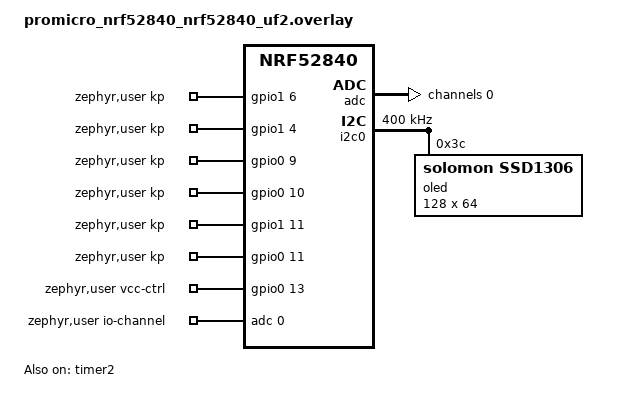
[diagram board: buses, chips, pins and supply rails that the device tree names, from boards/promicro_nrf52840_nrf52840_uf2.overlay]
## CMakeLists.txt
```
cmake_minimum_required(VERSION 3.20.0)
find_package(Zephyr REQUIRED HINTS $ENV{ZEPHYR_BASE})
project(zb_remote)
target_sources(app PRIVATE src/main.c src/buttons.c src/keypad.c src/battery.c src/led.c src/oled.c src/display_cluster.c src/font_terminus12.c src/icons.c)
target_include_directories(app PRIVATE src)
# record ZBOSS asserts (see __wrap_zb_assert in main.c)
zephyr_link_libraries(-Wl,--wrap=zb_assert)
```

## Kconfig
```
menu "zb-remote"
config APP_WAIT_HOST
	bool "Wait up to 20 s for USB host to open the console before starting"
config APP_RAM_PWRDN
	bool "Power down unused RAM"
endmenu
source "Kconfig.zephyr"
```

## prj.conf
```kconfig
CONFIG_GPIO=y
CONFIG_ADC=y
CONFIG_HEAP_MEM_POOL_SIZE=2048
CONFIG_MAIN_THREAD_PRIORITY=7

CONFIG_ZIGBEE_ADD_ON=y
CONFIG_ZIGBEE_APP_UTILS=y
CONFIG_ZIGBEE_ROLE_END_DEVICE=y
CONFIG_RAM_POWER_DOWN_LIBRARY=y

# Battery build (default): no USB, no console, no logs, start immediately.
# Development build with USB CDC logs: west build ... -- -DEXTRA_CONF_FILE=debug.conf
CONFIG_LOG=n
CONFIG_PRINTK=n
CONFIG_BOOT_BANNER=n
CONFIG_NCS_BOOT_BANNER=n
CONFIG_CONSOLE=n
CONFIG_UART_CONSOLE=n
CONFIG_SERIAL=n
CONFIG_USB_DEVICE_STACK=n
CONFIG_USB_DEVICE_STACK_NEXT=n
CONFIG_USB_CDC_ACM=n
CONFIG_APP_WAIT_HOST=n

# own k_sys_fatal_error_handler in main.c (records crash, reboots)
CONFIG_RESET_ON_FATAL_ERROR=n

# Pro Micro clones often have no 32.768 kHz crystal -> use internal RC (calibrated)
CONFIG_CLOCK_CONTROL_NRF_K32SRC_RC=y

# Scan all channels when joining (Z2M network is on channel 11)
CONFIG_ZIGBEE_CHANNEL_SELECTION_MODE_MULTI=y

# Z-Stack 3.x coordinator: classic Zigbee 3.0 (R22) association + transport key
CONFIG_ZIGBEE_PRO_CORE_BEHAVIOR_R22=y

# OLED
CONFIG_I2C=y
CONFIG_DISPLAY=y
CONFIG_HWINFO=y
```

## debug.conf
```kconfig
# Development overlay: logs over USB CDC ACM (/dev/cu.usbmodem*, 115200).
# west build -d build-debug -b promicro_nrf52840/nrf52840/uf2 . -- -DEXTRA_CONF_FILE=debug.conf
CONFIG_LOG=y
# deferred: logging never blocks the app when the USB host is not reading
CONFIG_LOG_MODE_DEFERRED=y
CONFIG_LOG_BUFFER_SIZE=4096
CONFIG_PRINTK=y
CONFIG_BOOT_BANNER=y
CONFIG_NCS_BOOT_BANNER=y
CONFIG_NCS_APPLICATION_BOOT_BANNER_STRING="zb-remote"
CONFIG_CONSOLE=y
CONFIG_UART_CONSOLE=y
CONFIG_SERIAL=y
CONFIG_UART_LINE_CTRL=y
# Legacy USB stack: the new device_next CDC does not enumerate on this Pro Micro clone
CONFIG_USB_DEVICE_STACK_NEXT=n
CONFIG_CDC_ACM_SERIAL_INITIALIZE_AT_BOOT=n
CONFIG_USB_DEVICE_STACK=y
CONFIG_USB_DEVICE_INITIALIZE_AT_BOOT=y
CONFIG_USB_CDC_ACM=y
CONFIG_USB_DEVICE_PRODUCT="zb-remote"
CONFIG_USB_DEVICE_PID=0x0004
# wait up to 20 s for the host to open the port so boot logs are not lost
CONFIG_APP_WAIT_HOST=y
```

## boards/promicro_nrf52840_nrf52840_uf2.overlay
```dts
/* Pro Micro nRF52840 (nice!nano clone), Adafruit UF2 bootloader + S140 v6 region kept.
 * Flash: 0x26000 app .. 0xD0000 | settings 8K | zboss_nvram 32K | zboss product cfg 4K | free | UF2 @0xF4000
 */
/delete-node/ &storage_partition;

&code_partition {
	reg = <0x00026000 0x000aa000>;
};

&flash0 {
	partitions {
		storage_partition: partition@d0000 {
			label = "storage";
			reg = <0x000d0000 0x00002000>;
		};
		zboss_nvram: partition@d2000 {
			label = "zboss-nvram";
			reg = <0x000d2000 0x00008000>;
		};
		zboss_product_config: partition@da000 {
			label = "zboss-product-config";
			reg = <0x000da000 0x00001000>;
		};
	};
};

/ {
	chosen {
		ncs,zigbee-timer = &timer2;
	};

	zephyr,user {
		/* Keypad: the 8 pads of the removed remote IC, pad 1..8 -> these pins (left header).
		 * Every pair of lines is scanned, buttons = pairs (see src/keymap.h). */
		kp-gpios = <&gpio1 6  GPIO_PULL_UP>,  /* 106 (left, bottom)   -> line 1 = IC GND */
			   <&gpio1 4  GPIO_PULL_UP>,  /* 104 (left, 2nd)      -> line 2 */
			   <&gpio0 9  GPIO_PULL_UP>,  /* 009 (right, bottom)  -> line 3 (NFC pin, board sets nfct-pins-as-gpios) */
			   <&gpio0 10 GPIO_PULL_UP>,  /* 010 (right, 2nd)     -> line 4 (NFC pin) */
			   <&gpio1 11 GPIO_PULL_UP>,  /* 111 (right, 3rd)     -> line 5 */
			   <&gpio0 11 GPIO_PULL_UP>;  /* 011 (left, 3rd)      -> line 6 */
		/* External VCC switch (powers the OLED) */
		vcc-ctrl-gpios = <&gpio0 13 GPIO_ACTIVE_HIGH>;
		io-channels = <&adc 0>;
	};
};

&timer2 {
	status = "okay";
};

/* UART0 (P0.09/P0.10) not used */
&uart0 {
	status = "disabled";
};

/* OLED on I2C0: SDA P0.17 (D2), SCL P0.20 (D3) */
&pinctrl {
	i2c0_default: i2c0_default {
		group1 {
			psels = <NRF_PSEL(TWIM_SDA, 0, 17)>,
				<NRF_PSEL(TWIM_SCL, 0, 20)>;
		};
	};
	i2c0_sleep: i2c0_sleep {
		group1 {
			psels = <NRF_PSEL(TWIM_SDA, 0, 17)>,
				<NRF_PSEL(TWIM_SCL, 0, 20)>;
			low-power-enable;
		};
	};
};

/* Battery: VDDH/5 */
&adc {
	#address-cells = <1>;
	#size-cells = <0>;
	status = "okay";
	channel@0 {
		reg = <0>;
		zephyr,gain = "ADC_GAIN_1_6";
		zephyr,reference = "ADC_REF_INTERNAL";
		zephyr,acquisition-time = <ADC_ACQ_TIME(ADC_ACQ_TIME_MICROSECONDS, 40)>;
		zephyr,input-positive = <NRF_SAADC_VDDHDIV5>;
		zephyr,resolution = <12>;
	};
};

/* Buttons use PORT/SENSE instead of GPIOTE IN channels (only 8 exist, we need 14) */
&gpio0 {
	sense-edge-mask = <0xffffffff>;
};
&gpio1 {
	sense-edge-mask = <0x0000ffff>;
};

/ {
	chosen {
		zephyr,display = &oled;
	};
};

&i2c0 {
	status = "okay";
	clock-frequency = <I2C_BITRATE_FAST>;
	oled: ssd1306@3c {
		compatible = "solomon,ssd1306";
		reg = <0x3c>;
		width = <128>;
		height = <64>;
		segment-offset = <0>;
		page-offset = <0>;
		display-offset = <0>;
		multiplex-ratio = <63>;
		segment-remap;
		com-invdir;
		prechargep = <0xf1>;
		zephyr,deferred-init;
	};
};
```

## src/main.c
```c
/* zb-remote: 14-button sleepy Zigbee remote (nRF52840 Pro Micro) for Zigbee2MQTT.
 *
 * Endpoint 1, HA profile, device "Remote Control":
 *   Basic, Identify, Power Config (battery), Multistate Input (button actions).
 * Button action -> Report Attributes genMultistateInput.presentValue = btn*10 + action
 *   action: 1 single, 2 double, 3 hold.
 */
#include <zephyr/kernel.h>
#include <zephyr/logging/log.h>
#include <stdio.h>

#include <zboss_api.h>
#include <zboss_api_addons.h>
#include <zigbee/zigbee_error_handler.h>
#include <zigbee/zigbee_app_utils.h>
#include <zb_nrf_platform.h>
#include <ram_pwrdn.h>

#include "buttons.h"
#include "keypad.h"
#include "keymap.h"
#include <zephyr/sys/reboot.h>
#include "battery.h"
#include "led.h"
#include "oled.h"
#include "display_cluster.h"
#include <zephyr/drivers/uart.h>
#include <zephyr/drivers/hwinfo.h>
#include <zephyr/fatal.h>
#include <zephyr/storage/flash_map.h>
#include <hal/nrf_power.h>
#include <zephyr/sys/reboot.h>

LOG_MODULE_REGISTER(app, LOG_LEVEL_INF);

/* last fatal error survives the software reset (noinit RAM) and is logged on the next boot */
static __noinit struct {
	uint32_t magic, reason, pc, lr, thread;
} crash;
#define CRASH_MAGIC 0xC0FFEE11

void k_sys_fatal_error_handler(unsigned int reason, const struct arch_esf *esf)
{
	crash.magic = CRASH_MAGIC;
	crash.reason = reason;
	crash.pc = esf ? esf->basic.pc : 0;
	crash.lr = esf ? esf->basic.lr : 0;
	crash.thread = (uint32_t)k_current_get();
	sys_reboot(SYS_REBOOT_COLD);
}

/* ZBOSS internal assert (linked with --wrap=zb_assert) -> remembered across the reset */
extern void __real_zb_assert(zb_uint16_t file_id, zb_int_t line);
void __wrap_zb_assert(zb_uint16_t file_id, zb_int_t line)
{
	crash.magic = CRASH_MAGIC;
	crash.reason = 0xA55E;
	crash.pc = file_id;
	crash.lr = (uint32_t)line;
	crash.thread = 0;
	if (!k_is_in_isr()) {
		LOG_ERR("ZBOSS assert file_id %u line %d, rebooting in 1 s", file_id, line);
		k_msleep(1000); /* let the USB console flush the log */
	}
	__real_zb_assert(file_id, line);
}


/* file_id 122 = zb_nvram.c: corrupted NVRAM makes ZBOSS assert on every boot.
 * Wipe the partition once so the stack starts clean (network has to be re-joined). */
#define ZB_FILE_ID_NVRAM 122
static int erase_partition(uint8_t id, const char *name)
{
	const struct flash_area *fa;
	int err = flash_area_open(id, &fa);
	if (!err) {
		err = flash_area_erase(fa, 0, fa->fa_size);
		flash_area_close(fa);
	}
	LOG_WRN("%s erased: %d", name, err);
	return err;
}

/* NVRAM datasets are encrypted with a PSA master key kept in trusted storage (settings/NVS
 * in the "storage" partition); if either is corrupted the stack asserts while saving keys.
 * Wipe both together: the device leaves the network and has to be re-joined. */
static void nvram_self_heal(void)
{
	erase_partition(FIXED_PARTITION_ID(zboss_nvram), "zboss nvram");
	erase_partition(FIXED_PARTITION_ID(storage_partition), "settings storage (PSA ITS)");
	/* settings/NVS may already be mounted on the old content -> restart clean */
	crash.magic = 0;
	k_msleep(500);
	sys_reboot(SYS_REBOOT_COLD);
}


#define EP                 1
#define DEVICE_ID          0x0006 /* HA Remote Control */
#define LONG_POLL_MS       5000
#define FAST_POLL_MS       100   /* while the screen is on after a press */
#define FAST_POLL_FOR      K_SECONDS(10)
#define BATTERY_PERIOD     K_HOURS(1)


/* ---------- attributes ---------- */
static struct {
	zb_uint8_t zcl_version;
	zb_uint8_t app_version;
	zb_uint8_t stack_version;
	zb_uint8_t hw_version;
	zb_char_t mf_name[16];
	zb_char_t model_id[16];
	zb_char_t date_code[10];
	zb_uint8_t power_source;
	zb_char_t location_id[2];
	zb_uint8_t ph_env;
	zb_char_t sw_build_id[12];
} basic;

static zb_uint16_t identify_time;

static struct {
	zb_uint8_t voltage;       /* 100 mV units */
	zb_uint8_t size;
	zb_uint8_t quantity;
	zb_uint8_t rated_voltage;
	zb_uint8_t alarm_mask;
	zb_uint8_t voltage_min_th;
	zb_uint8_t remaining;     /* 0.5 % units */
	zb_uint8_t th1, th2, th3, min_th, pth1, pth2, pth3;
	zb_uint32_t alarm_state;
} batt;

static struct {
	zb_char_t description[2];
	zb_uint16_t num_states;
	zb_bool_t out_of_service;
	zb_uint16_t present_value;
	zb_uint8_t reliability;
	zb_uint8_t status_flags;
	zb_uint32_t app_type;
} msi;

ZB_ZCL_DECLARE_BASIC_ATTRIB_LIST_EXT(basic_attr_list, &basic.zcl_version, &basic.app_version,
	&basic.stack_version, &basic.hw_version, basic.mf_name, basic.model_id, basic.date_code,
	&basic.power_source, basic.location_id, &basic.ph_env, basic.sw_build_id);

ZB_ZCL_DECLARE_IDENTIFY_ATTRIB_LIST(identify_attr_list, &identify_time);

ZB_ZCL_START_DECLARE_ATTRIB_LIST_CLUSTER_REVISION(power_attr_list, ZB_ZCL_POWER_CONFIG)
ZB_ZCL_POWER_CONFIG_BATTERY_ATTRIB_LIST_EXT(, &batt.voltage, &batt.size,
	&batt.quantity, &batt.rated_voltage, &batt.alarm_mask, &batt.voltage_min_th, &batt.remaining,
	&batt.th1, &batt.th2, &batt.th3, &batt.min_th, &batt.pth1, &batt.pth2, &batt.pth3,
	&batt.alarm_state)
ZB_ZCL_FINISH_DECLARE_ATTRIB_LIST;

ZB_ZCL_DECLARE_MULTI_INPUT_ATTRIB_LIST(msi_attr_list, msi.description, &msi.num_states,
	&msi.out_of_service, &msi.present_value, &msi.reliability, &msi.status_flags, &msi.app_type);

static zb_zcl_cluster_desc_t clusters[] = {
	ZB_ZCL_CLUSTER_DESC(ZB_ZCL_CLUSTER_ID_BASIC, ZB_ZCL_ARRAY_SIZE(basic_attr_list, zb_zcl_attr_t),
			    basic_attr_list, ZB_ZCL_CLUSTER_SERVER_ROLE, ZB_ZCL_MANUF_CODE_INVALID),
	ZB_ZCL_CLUSTER_DESC(ZB_ZCL_CLUSTER_ID_IDENTIFY,
			    ZB_ZCL_ARRAY_SIZE(identify_attr_list, zb_zcl_attr_t), identify_attr_list,
			    ZB_ZCL_CLUSTER_SERVER_ROLE, ZB_ZCL_MANUF_CODE_INVALID),
	ZB_ZCL_CLUSTER_DESC(ZB_ZCL_CLUSTER_ID_POWER_CONFIG,
			    ZB_ZCL_ARRAY_SIZE(power_attr_list, zb_zcl_attr_t), power_attr_list,
			    ZB_ZCL_CLUSTER_SERVER_ROLE, ZB_ZCL_MANUF_CODE_INVALID),
	ZB_ZCL_CLUSTER_DESC(ZB_ZCL_CLUSTER_ID_MULTI_INPUT,
			    ZB_ZCL_ARRAY_SIZE(msi_attr_list, zb_zcl_attr_t), msi_attr_list,
			    ZB_ZCL_CLUSTER_SERVER_ROLE, ZB_ZCL_MANUF_CODE_INVALID),
	ZB_ZCL_CLUSTER_DESC(ZB_ZCL_CLUSTER_ID_REMOTE_DISPLAY, DISPLAY_ATTR_COUNT, display_attr_list,
			    ZB_ZCL_CLUSTER_SERVER_ROLE, ZB_ZCL_MANUF_CODE_INVALID),
};

ZB_DECLARE_SIMPLE_DESC(5, 0);
ZB_AF_SIMPLE_DESC_TYPE(5, 0) simple_desc_remote = {
	EP, ZB_AF_HA_PROFILE_ID, DEVICE_ID, 0, 0, 5, 0,
	{ ZB_ZCL_CLUSTER_ID_BASIC, ZB_ZCL_CLUSTER_ID_IDENTIFY, ZB_ZCL_CLUSTER_ID_POWER_CONFIG,
	  ZB_ZCL_CLUSTER_ID_MULTI_INPUT, ZB_ZCL_CLUSTER_ID_REMOTE_DISPLAY }
};

ZB_AF_DECLARE_ENDPOINT_DESC(remote_ep, EP, ZB_AF_HA_PROFILE_ID, 0, NULL,
	ZB_ZCL_ARRAY_SIZE(clusters, zb_zcl_cluster_desc_t), clusters,
	(zb_af_simple_desc_1_1_t *)&simple_desc_remote, 0, NULL, 0, NULL);

ZBOSS_DECLARE_DEVICE_CTX_1_EP(remote_ctx, remote_ep);

static void attrs_init(void)
{
	basic.zcl_version = ZB_ZCL_VERSION;
	basic.app_version = 1;
	basic.stack_version = 1;
	basic.hw_version = 1;
	ZB_ZCL_SET_STRING_VAL(basic.mf_name, "heartpolik", ZB_ZCL_STRING_CONST_SIZE("heartpolik"));
	ZB_ZCL_SET_STRING_VAL(basic.model_id, "zb-remote-14", ZB_ZCL_STRING_CONST_SIZE("zb-remote-14"));
	ZB_ZCL_SET_STRING_VAL(basic.date_code, "20261117", ZB_ZCL_STRING_CONST_SIZE("20261117"));
	ZB_ZCL_SET_STRING_VAL(basic.sw_build_id, "0.1.0", ZB_ZCL_STRING_CONST_SIZE("0.1.0"));
	basic.power_source = ZB_ZCL_BASIC_POWER_SOURCE_BATTERY;
	basic.ph_env = ZB_ZCL_BASIC_PHYSICAL_ENVIRONMENT_DEFAULT_VALUE;

	identify_time = ZB_ZCL_IDENTIFY_IDENTIFY_TIME_DEFAULT_VALUE;

	batt.size = ZB_ZCL_POWER_CONFIG_BATTERY_SIZE_OTHER;
	batt.quantity = 1;
	batt.rated_voltage = 37;
	batt.voltage = 0xff;
	batt.remaining = 0xff;

	msi.num_states = 14 * 10 + 3;
	msi.out_of_service = ZB_FALSE;
	msi.reliability = ZB_ZCL_MULTI_INPUT_RELIABILITY_NO_FAULT_DETECTED;
	msi.status_flags = ZB_ZCL_MULTI_INPUT_STATUS_FLAG_NORMAL;
}

/* ---------- manual attribute reports to the coordinator ---------- */
struct report_req {
	zb_uint16_t cluster;
	zb_uint8_t n;
	struct { zb_uint16_t id; zb_uint8_t type; zb_uint16_t val; } a[2];
};

#define REPORT_Q_LEN 16
K_MSGQ_DEFINE(report_q, sizeof(struct report_req), REPORT_Q_LEN, 4);

static void send_report_buf(zb_cb_param_t bufid)
{
	zb_bufid_t buf = (zb_bufid_t)bufid;
	struct report_req r;
	zb_uint16_t dst = 0x0000;
	if (k_msgq_get(&report_q, &r, K_NO_WAIT)) {
		zb_buf_free(buf);
		return;
	}

	zb_uint8_t *ptr = ZB_ZCL_START_PACKET(buf);
	ZB_ZCL_CONSTRUCT_GENERAL_COMMAND_RESP_FRAME_CONTROL(ptr);
	ZB_ZCL_CONSTRUCT_COMMAND_HEADER(ptr, ZB_ZCL_GET_SEQ_NUM(), ZB_ZCL_CMD_REPORT_ATTRIB);
	for (int i = 0; i < r.n; i++) {
		ZB_ZCL_PACKET_PUT_DATA16_VAL(ptr, r.a[i].id);
		ZB_ZCL_PACKET_PUT_DATA8(ptr, r.a[i].type);
		if (r.a[i].type == ZB_ZCL_ATTR_TYPE_U16) {
			ZB_ZCL_PACKET_PUT_DATA16_VAL(ptr, r.a[i].val);
		} else {
			ZB_ZCL_PACKET_PUT_DATA8(ptr, (zb_uint8_t)r.a[i].val);
		}
	}
	ZB_ZCL_FINISH_N_SEND_PACKET(buf, ptr, dst, ZB_APS_ADDR_MODE_16_ENDP_PRESENT, 1, EP,
				    ZB_AF_HA_PROFILE_ID, r.cluster, NULL);
}

static void request_send(zb_cb_param_t unused)
{
	ZVUNUSED(unused);
	zb_buf_get_out_delayed_ext(send_report_buf, 0, 0);
}

static void queue_report(const struct report_req *r)
{
	if (k_msgq_put(&report_q, r, K_NO_WAIT)) {
		LOG_WRN("report queue full");
		return;
	}
	if (ZB_JOINED()) {
		zigbee_schedule_callback(request_send, 0);
	} else {
		LOG_INF("not joined yet, report queued");
	}
}

static void flush_reports(void)
{
	for (uint32_t i = k_msgq_num_used_get(&report_q); i > 0; i--) {
		zigbee_schedule_callback(request_send, 0);
	}
}

/* ---------- battery ---------- */
static int last_pct = -1;
bool ha_tiles; /* set once HA wrote any tile */
static bool usb_present(void)
{
	return nrf_power_usbregstatus_vbusdet_get(NRF_POWER);
}

static void battery_update(void)
{
	if (usb_present()) {
		/* VDDH is fed from VBUS: the reading is USB voltage, not the cell */
		LOG_INF("on USB power, battery report skipped");
		return;
	}
	int mv = battery_mv();
	if (mv < 0) {
		LOG_WRN("battery read failed: %d", mv);
		return;
	}
	uint8_t pct = battery_percent(mv);
	batt.voltage = MIN(mv / 100, 0xfe);
	batt.remaining = MIN(pct * 2, 200);
	LOG_INF("battery %d mV, %d %%", mv, pct);
	last_pct = pct;
	ui_set_status(pct, ZB_JOINED());


	struct report_req r = {
		.cluster = ZB_ZCL_CLUSTER_ID_POWER_CONFIG, .n = 2,
		.a = {
			{ ZB_ZCL_ATTR_POWER_CONFIG_BATTERY_VOLTAGE_ID, ZB_ZCL_ATTR_TYPE_U8, batt.voltage },
			{ ZB_ZCL_ATTR_POWER_CONFIG_BATTERY_PERCENTAGE_REMAINING_ID, ZB_ZCL_ATTR_TYPE_U8,
			  batt.remaining },
		},
	};
	queue_report(&r);
}

static void battery_work_fn(struct k_work *w);
static K_WORK_DELAYABLE_DEFINE(battery_work, battery_work_fn);
static int64_t last_battery_ms = -1;

static void battery_work_fn(struct k_work *w)
{
	battery_update();
	last_battery_ms = k_uptime_get();
	k_work_reschedule(&battery_work, BATTERY_PERIOD);
}

/* ---------- USB power (charging) ---------- */
#define POWER_POLL K_SECONDS(3)
static int on_usb = -1; /* unknown until the first check -> always reported once */

static void power_work_fn(struct k_work *w);
static K_WORK_DELAYABLE_DEFINE(power_work, power_work_fn);

static void power_work_fn(struct k_work *w)
{
	bool u = usb_present();

	if ((int)u != on_usb) {
		bool unplugged = on_usb == 1;

		on_usb = u;
		LOG_INF("USB power %s", u ? "connected" : "removed");
		ui_set_charging(u);
		display_set_charging(u);
		struct report_req r = {
			.cluster = ZB_ZCL_CLUSTER_ID_REMOTE_DISPLAY, .n = 1,
			.a = { { DISPLAY_ATTR_CHARGING, ZB_ZCL_ATTR_TYPE_U8, u } },
		};
		queue_report(&r);
		if (unplugged) {
			/* real cell voltage again: measure once it settles */
			k_work_reschedule(&battery_work, K_SECONDS(2));
		}
	}
	k_work_reschedule(&power_work, POWER_POLL);
}

/* ---------- buttons ---------- */
/* Fixed fast polling while the user looks at the screen. ZBOSS turbo poll is adaptive:
 * the interval grows from 100-250 ms up to 3 s, so an answer from HA that arrives ~1 s after
 * the press waited 2+ s in the parent's queue. Long poll is restored when the window ends. */
static void set_poll(zb_cb_param_t ms)
{
	zb_zdo_pim_set_long_poll_interval(ms);
}

static void slow_poll_fn(struct k_work *w)
{
	zigbee_schedule_callback(set_poll, LONG_POLL_MS);
}
static K_WORK_DELAYABLE_DEFINE(slow_poll_work, slow_poll_fn);

static void fast_poll(void)
{
	if (!k_work_delayable_is_pending(&slow_poll_work)) {
		zigbee_schedule_callback(set_poll, FAST_POLL_MS);
	}
	k_work_reschedule(&slow_poll_work, FAST_POLL_FOR);
}

static void on_button(uint8_t btn, enum btn_action action)
{
	static const char *names[] = { "", "single", "double", "hold" };
	uint16_t value = btn * 10 + action;

	LOG_INF("button %u %s -> %u", btn, names[action], value);
	led_blink(1, 30, 0);
	if (!ha_tiles) {
		char b[24];
		snprintf(b, sizeof(b), "button|%u%s", btn, action == BTN_DOUBLE ? " x2" : action == BTN_HOLD ? " д" : "");
		ui_set_tile(1, b);
	}
	if (ui_alert_active()) {
		ui_clear_alert(); /* any button dismisses the alert locally */
	}
	oled_wake(0);
	msi.present_value = value;

	struct report_req r = {
		.cluster = ZB_ZCL_CLUSTER_ID_MULTI_INPUT, .n = 1,
		.a = { { ZB_ZCL_ATTR_MULTI_INPUT_PRESENT_VALUE_ID, ZB_ZCL_ATTR_TYPE_U16, value } },
	};
	queue_report(&r);
	/* stay responsive while the screen is on so HA's answer shows up at once */
	fast_poll();

	if (last_battery_ms < 0 || k_uptime_get() - last_battery_ms > 10 * 60 * 1000) {
		k_work_reschedule(&battery_work, K_MSEC(500));
	}
}

/* ---------- keypad raw pairs: learn view + factory reset ---------- */
static bool keymap_empty(void)
{
	for (int k = 0; k < 14; k++) {
		if (keymap[k][0] >= 0) {
			return false;
		}
	}
	return true;
}

static void factory_reset_fn(struct k_work *w)
{
	LOG_WRN("factory reset: leaving network");
	zigbee_erase_persistent_storage(ZB_TRUE);
	k_msleep(200);
	sys_reboot(SYS_REBOOT_COLD);
}
static K_WORK_DELAYABLE_DEFINE(factory_reset_work, factory_reset_fn);

static void on_raw_pair(int a, int b, bool pressed)
{
	/* hold key 1 (or any pair while the keymap is empty) for 10 s -> factory reset */
	bool is_key1 = (keymap[0][0] == a && keymap[0][1] == b) || (keymap[0][0] == b && keymap[0][1] == a);
	if (is_key1 || keymap_empty()) {
		if (pressed) {
			k_work_reschedule(&factory_reset_work, K_SECONDS(10));
		} else {
			k_work_cancel_delayable(&factory_reset_work);
		}
	}
	if (pressed && keymap_empty()) {
		char l[24];
		snprintf(l, sizeof(l), "пади %d-%d", a + 1, b + 1);
		ui_set_tile(1, "");
		char spec[40];
		snprintf(spec, sizeof(spec), "button|%s", l);
		ui_set_tile(0, spec);
		oled_wake(0);
		led_blink(1, 30, 0);
	}
}

/* ---------- zigbee signals ---------- */
void zboss_signal_handler(zb_cb_param_t bufid)
{
	zb_zdo_app_signal_hdr_t *hdr = NULL;
	zb_zdo_app_signal_type_t sig = zb_get_app_signal(bufid, &hdr);
	zb_ret_t status = ZB_GET_APP_SIGNAL_STATUS(bufid);

	if (sig != ZB_COMMON_SIGNAL_CAN_SLEEP) {
		LOG_INF("zb signal %d status %d", sig, status);
	}

	switch (sig) {
	case ZB_BDB_SIGNAL_DEVICE_REBOOT:
	case ZB_BDB_SIGNAL_STEERING:
		if (status == RET_OK && ZB_JOINED()) {
			LOG_INF("joined network, PAN 0x%04x", ZB_PIBCACHE_PAN_ID());
			led_searching(false);
			led_blink(3, 100, 150);
			ui_set_status(last_pct, true);
			if (!ha_tiles) {
				ui_set_tile(0, "link|OK");
			}
			flush_reports();
			zb_zdo_pim_set_long_poll_interval(LONG_POLL_MS);
			k_work_reschedule(&battery_work, K_SECONDS(3));
		}
		if (status != RET_OK) {
			led_searching(true);
		}
		break;
	case ZB_ZDO_SIGNAL_LEAVE:
		LOG_INF("left network");
		ui_set_status(last_pct, false);
		led_searching(true);
		break;
	default:
		break;
	}

	ZB_ERROR_CHECK(zigbee_default_signal_handler(bufid));
	if (bufid) {
		zb_buf_free(bufid);
	}
}

static void wait_for_host(void)
{
#if defined(CONFIG_UART_LINE_CTRL)
	const struct device *con = DEVICE_DT_GET(DT_CHOSEN(zephyr_console));
	uint32_t dtr = 0;
	for (int i = 0; i < 200 && !dtr; i++) {
		uart_line_ctrl_get(con, UART_LINE_CTRL_DTR, &dtr);
		k_msleep(100);
	}
#endif
}

int main(void)
{
	if (IS_ENABLED(CONFIG_APP_WAIT_HOST)) {
		wait_for_host();
	}
	uint32_t rc = 0;
	hwinfo_get_reset_cause(&rc);
	hwinfo_clear_reset_cause();
	LOG_INF("zb-remote starting, reset cause 0x%08x", rc);
	if (crash.magic == CRASH_MAGIC) {
		if (crash.reason == 0xA55E) {
			LOG_ERR("previous ZBOSS assert: file_id %u line %u", crash.pc, crash.lr);
			if (crash.pc == ZB_FILE_ID_NVRAM) {
				nvram_self_heal();
			}
		} else {
			LOG_ERR("previous crash: reason %u pc 0x%08x lr 0x%08x thread 0x%08x",
				crash.reason, crash.pc, crash.lr, crash.thread);
		}
		crash.magic = 0;
	}
	led_init();
	led_blink(1, 1000, 0);
	if (oled_init() == 0) {
		ui_set_tile(0, "search|…");
		ui_set_tile(1, "button|—");
		oled_wake(15000);
	}

	k_work_reschedule(&power_work, K_NO_WAIT);

	buttons_init(on_button);
	int kerr = keypad_init(on_raw_pair);
	if (kerr) {
		LOG_ERR("keypad init failed: %d", kerr);
	}

	zigbee_configure_sleepy_behavior(true);
	ZB_AF_REGISTER_DEVICE_CTX(&remote_ctx);
	attrs_init();

	if (IS_ENABLED(CONFIG_APP_RAM_PWRDN)) {
		power_down_unused_ram();
	}

	led_searching(true);
	zigbee_enable();
	LOG_INF("zigbee enabled");
	return 0;
}
```

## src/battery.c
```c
#include <zephyr/kernel.h>
#include <zephyr/drivers/adc.h>
#include "battery.h"

static const struct adc_dt_spec ch = ADC_DT_SPEC_GET_BY_IDX(DT_PATH(zephyr_user), 0);

int battery_mv(void)
{
	int16_t raw;
	struct adc_sequence seq = { .buffer = &raw, .buffer_size = sizeof(raw) };
	static bool inited;

	if (!inited) {
		if (!adc_is_ready_dt(&ch) || adc_channel_setup_dt(&ch)) {
			return -ENODEV;
		}
		inited = true;
	}
	adc_sequence_init_dt(&ch, &seq);
	if (adc_read_dt(&ch, &seq)) {
		return -EIO;
	}
	int32_t mv = raw;
	adc_raw_to_millivolts_dt(&ch, &mv);
	return mv * 5; /* VDDH/5 */
}

uint8_t battery_percent(int mv)
{
	/* rough LiPo discharge curve */
	static const struct { int mv; uint8_t pct; } t[] = {
		{4200, 100}, {4100, 90}, {4000, 80}, {3900, 65}, {3800, 50},
		{3700, 30}, {3600, 15}, {3500, 5}, {3300, 0},
	};
	if (mv >= t[0].mv) {
		return 100;
	}
	for (int i = 1; i < ARRAY_SIZE(t); i++) {
		if (mv >= t[i].mv) {
			return t[i].pct + (mv - t[i].mv) * (t[i - 1].pct - t[i].pct) /
					  (t[i - 1].mv - t[i].mv);
		}
	}
	return 0;
}
```

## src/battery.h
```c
#pragma once
#include <stdint.h>
/* Returns battery millivolts (VDDH) or <0 on error */
int battery_mv(void);
/* LiPo 0..100 % estimate */
uint8_t battery_percent(int mv);
```

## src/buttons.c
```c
/* Click detection (single / double / hold) on top of any debounced key source. */
#include <zephyr/kernel.h>
#include "buttons.h"

#define HOLD_MS   600
#define DOUBLE_MS 300

/* Buttons without a double click: single is sent right on release (no 300 ms wait for a
 * second click). Hold still works. Bit (n-1) = button n: the d-pad 4-8 (☼ up/down, room ◀ ▶,
 * ☾ in the centre), pressed in quick series. All other buttons keep double click. */
#define NO_DOUBLE_MASK (BIT(4 - 1) | BIT(5 - 1) | BIT(6 - 1) | BIT(7 - 1) | BIT(8 - 1))

struct btn_state {
	struct k_work_delayable timer;
	bool pressed;
	bool hold_fired;
	uint8_t clicks;
};

static struct btn_state st[BTN_MAX];
static btn_cb_t user_cb;

static void timer_fn(struct k_work *w)
{
	struct btn_state *s = CONTAINER_OF(k_work_delayable_from_work(w), struct btn_state, timer);
	int i = s - st;

	if (s->pressed) {
		s->hold_fired = true;
		s->clicks = 0;
		user_cb(i + 1, BTN_HOLD);
	} else if (s->clicks) {
		user_cb(i + 1, s->clicks >= 2 ? BTN_DOUBLE : BTN_SINGLE);
		s->clicks = 0;
	}
}

void buttons_feed(uint8_t btn, bool now)
{
	if (btn < 1 || btn > BTN_MAX) {
		return;
	}
	struct btn_state *s = &st[btn - 1];

	if (now == s->pressed) {
		return;
	}
	s->pressed = now;
	if (now) {
		s->hold_fired = false;
		k_work_reschedule(&s->timer, K_MSEC(HOLD_MS));
	} else if (s->hold_fired) {
		k_work_cancel_delayable(&s->timer);
	} else if (NO_DOUBLE_MASK & BIT(btn - 1)) {
		k_work_cancel_delayable(&s->timer);
		s->clicks = 0;
		user_cb(btn, BTN_SINGLE);
	} else if (++s->clicks >= 2) {
		k_work_cancel_delayable(&s->timer);
		s->clicks = 0;
		user_cb(btn, BTN_DOUBLE);
	} else {
		k_work_reschedule(&s->timer, K_MSEC(DOUBLE_MS));
	}
}

bool buttons_any_pressed(void)
{
	for (int i = 0; i < BTN_MAX; i++) {
		if (st[i].pressed) {
			return true;
		}
	}
	return false;
}

void buttons_init(btn_cb_t cb)
{
	user_cb = cb;
	for (int i = 0; i < BTN_MAX; i++) {
		k_work_init_delayable(&st[i].timer, timer_fn);
	}
}
```

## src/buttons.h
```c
#pragma once
#include <stdint.h>
#include <stdbool.h>

#define BTN_MAX 14

enum btn_action { BTN_SINGLE = 1, BTN_DOUBLE = 2, BTN_HOLD = 3 };

/* Called from the system work queue. btn is 1-based. */
typedef void (*btn_cb_t)(uint8_t btn, enum btn_action action);

void buttons_init(btn_cb_t cb);
/* Feed debounced physical state of button (1-based) */
void buttons_feed(uint8_t btn, bool pressed);
bool buttons_any_pressed(void);
```

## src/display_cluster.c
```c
#include <zephyr/kernel.h>
#include <zephyr/logging/log.h>
#include <string.h>
#include <zboss_api.h>
#include "display_cluster.h"
#include "oled.h"

LOG_MODULE_REGISTER(dispcl, LOG_LEVEL_INF);

static zb_uint8_t tile_attr[3][1 + DISPLAY_SPEC_BYTES];
static zb_uint8_t alert_attr[1 + DISPLAY_SPEC_BYTES];
static zb_uint8_t title_attr[1 + DISPLAY_SPEC_BYTES];
static zb_uint8_t wake_attr, flip_attr, charging_attr, focus_attr;
static zb_int8_t xoff_attr, yoff_attr;
static zb_uint16_t cluster_rev = 1;

#define RW ZB_ZCL_ATTR_ACCESS_READ_WRITE
#define NM ZB_ZCL_NON_MANUFACTURER_SPECIFIC
zb_zcl_attr_t display_attr_list[] = {
	{ ZB_ZCL_ATTR_GLOBAL_CLUSTER_REVISION_ID, ZB_ZCL_ATTR_TYPE_U16, ZB_ZCL_ATTR_ACCESS_READ_ONLY, NM,
	  &cluster_rev },
	{ 0x0000, ZB_ZCL_ATTR_TYPE_OCTET_STRING, RW, NM, tile_attr[0] },
	{ 0x0001, ZB_ZCL_ATTR_TYPE_OCTET_STRING, RW, NM, tile_attr[1] },
	{ 0x0002, ZB_ZCL_ATTR_TYPE_OCTET_STRING, RW, NM, tile_attr[2] },
	{ 0x0003, ZB_ZCL_ATTR_TYPE_U8, RW, NM, &wake_attr },
	{ 0x0004, ZB_ZCL_ATTR_TYPE_OCTET_STRING, RW, NM, alert_attr },
	{ 0x0005, ZB_ZCL_ATTR_TYPE_U8, RW, NM, &flip_attr },
	{ 0x0006, ZB_ZCL_ATTR_TYPE_S8, RW, NM, &xoff_attr },
	{ 0x0007, ZB_ZCL_ATTR_TYPE_S8, RW, NM, &yoff_attr },
	{ 0x0009, ZB_ZCL_ATTR_TYPE_OCTET_STRING, RW, NM, title_attr },
	{ DISPLAY_ATTR_CHARGING, ZB_ZCL_ATTR_TYPE_U8, ZB_ZCL_ATTR_ACCESS_READ_ONLY, NM, &charging_attr },
	{ 0x000B, ZB_ZCL_ATTR_TYPE_U8, RW, NM, &focus_attr },
	{ ZB_ZCL_NULL_ID, 0, 0, NM, NULL },
};
BUILD_ASSERT(ARRAY_SIZE(display_attr_list) == DISPLAY_ATTR_COUNT);

static bool is_str(zb_uint16_t id)
{
	return id <= 0x0002 || id == 0x0004 || id == 0x0009;
}

static zb_ret_t check_value(zb_uint16_t attr_id, zb_uint8_t ep, zb_uint8_t *value)
{
	if (is_str(attr_id) && value[0] > DISPLAY_SPEC_BYTES) {
		return RET_ERROR;
	}
	return RET_OK;
}

static void write_hook(zb_uint8_t ep, zb_uint16_t attr_id, zb_uint8_t *v, zb_uint16_t manuf)
{
	char tmp[DISPLAY_SPEC_BYTES + 1];

	if (is_str(attr_id)) {
		uint8_t n = MIN(v[0], DISPLAY_SPEC_BYTES);
		memcpy(tmp, &v[1], n);
		tmp[n] = 0;
		LOG_INF("attr 0x%04x = \"%s\"", attr_id, tmp);
		if (attr_id == 0x0009) {
			ui_set_title(tmp);
		} else if (attr_id == 0x0004) {
			ui_set_alert(tmp);
		} else {
			extern bool ha_tiles;
			ha_tiles = true;
			ui_set_tile(attr_id, tmp);
		}
	} else if (attr_id == 0x0003 && v[0]) {
		oled_wake(v[0] * 1000);
	} else if (attr_id == 0x000B) {
		ui_set_focus(v[0]);
	} else if (attr_id == 0x0005) {
		ui_set_flip(v[0] != 0);
	} else if (attr_id == 0x0006) {
		ui_set_offset((int8_t)v[0], yoff_attr);
	} else if (attr_id == 0x0007) {
		ui_set_offset(xoff_attr, (int8_t)v[0]);
	}
}

void display_set_charging(bool c)
{
	charging_attr = c ? 1 : 0;
}

void display_cluster_init(void)
{
	zb_zcl_add_cluster_handlers(ZB_ZCL_CLUSTER_ID_REMOTE_DISPLAY, ZB_ZCL_CLUSTER_SERVER_ROLE,
				    check_value, write_hook, NULL);
}
```

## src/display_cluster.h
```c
#pragma once
#include <zboss_api.h>

/* Custom cluster 0xFC10 "remote display" (server), all RW:
 *   0x0000..0x0002 octet string  tile 1..3 "icon|text"            (UTF-8, <=48 B)
 *   0x0003         uint8         wake: screen on for N seconds
 *   0x0004         octet string  alert "icon|l1|l2|l3", empty = clear
 *   0x0005         uint8         flip: 1 = rotate 180°
 *   0x0006         int8          x offset (px), 0x0007 int8 y offset (px); shows a frame for 20 s
 *   0x0009         octet string  title: header text in the yellow band (e.g. room), empty = battery %
 *   0x000A         uint8 (RO)    charging: 1 = USB power present (reported on change)
 *   0x000B         uint8         focus: tile 1..3 whose value the d-pad changes (inverted), 0 = none
 */
#define ZB_ZCL_CLUSTER_ID_REMOTE_DISPLAY 0xFC10
#define DISPLAY_SPEC_BYTES 48

void display_cluster_init(void);
#define ZB_ZCL_CLUSTER_ID_REMOTE_DISPLAY_SERVER_ROLE_INIT display_cluster_init
#define ZB_ZCL_CLUSTER_ID_REMOTE_DISPLAY_CLIENT_ROLE_INIT NULL

extern zb_zcl_attr_t display_attr_list[];
#define DISPLAY_ATTR_COUNT 13
#define DISPLAY_ATTR_CHARGING 0x000A
void display_set_charging(bool c);
```

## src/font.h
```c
#pragma once
#include <stdint.h>

struct font_glyph {
	uint16_t cp;     /* unicode code point */
	uint8_t adv;     /* advance width */
	uint8_t w;       /* bitmap columns */
	uint16_t off;    /* offset into data */
};

struct font {
	uint8_t height;  /* rows; each column = ceil(height/8) bytes, LSB = top */
	uint8_t ascent;
	const struct font_glyph *glyphs;
	uint16_t count;
	const uint8_t *data;
};

extern const struct font font_main;
```

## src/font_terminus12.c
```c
/* generated by tools/genfont.py from TerminusTTF-4.49.3.ttf @12px */
#include "font.h"

static const uint8_t font_data[] = {
	0x00, 0x00, 0x00, 0x00, 0x00, 0x00, 0x00, 0x00, 0x00, 0x00, 0x00, 0x00, 0x00, 0x00, 0x00, 0x00,
	0x7c, 0x03, 0x00, 0x00, 0x00, 0x00, 0x00, 0x00, 0x00, 0x00, 0x0e, 0x00, 0x00, 0x00, 0x0e, 0x00,
	0x00, 0x00, 0x00, 0x00, 0x90, 0x00, 0xfc, 0x03, 0x90, 0x00, 0xfc, 0x03, 0x90, 0x00, 0x00, 0x00,
	0x30, 0x01, 0x48, 0x02, 0xfc, 0x07, 0x48, 0x02, 0x90, 0x01, 0x00, 0x00, 0x08, 0x00, 0x14, 0x03,
	0xc8, 0x00, 0x30, 0x01, 0x8c, 0x02, 0x00, 0x01, 0x80, 0x01, 0x58, 0x02, 0x64, 0x02, 0x98, 0x01,
	0x40, 0x02, 0x00, 0x00, 0x00, 0x00, 0x00, 0x00, 0x0e, 0x00, 0x00, 0x00, 0x00, 0x00, 0x00, 0x00,
	0x00, 0x00, 0xf0, 0x00, 0x08, 0x01, 0x04, 0x02, 0x00, 0x00, 0x00, 0x00, 0x00, 0x00, 0x04, 0x02,
	0x08, 0x01, 0xf0, 0x00, 0x00, 0x00, 0x00, 0x00, 0x40, 0x00, 0x50, 0x01, 0xe0, 0x00, 0x50, 0x01,
	0x40, 0x00, 0x00, 0x00, 0x40, 0x00, 0x40, 0x00, 0xf0, 0x01, 0x40, 0x00, 0x40, 0x00, 0x00, 0x00,
	0x00, 0x00, 0x00, 0x04, 0x00, 0x03, 0x00, 0x00, 0x00, 0x00, 0x00, 0x00, 0x40, 0x00, 0x40, 0x00,
	0x40, 0x00, 0x40, 0x00, 0x40, 0x00, 0x00, 0x00, 0x00, 0x00, 0x00, 0x00, 0x00, 0x03, 0x00, 0x00,
	0x00, 0x00, 0x00, 0x00, 0x00, 0x00, 0x00, 0x03, 0xc0, 0x00, 0x30, 0x00, 0x0c, 0x00, 0x00, 0x00,
	0xf8, 0x01, 0x44, 0x02, 0x24, 0x02, 0x14, 0x02, 0xf8, 0x01, 0x00, 0x00, 0x00, 0x00, 0x08, 0x02,
	0xfc, 0x03, 0x00, 0x02, 0x00, 0x00, 0x00, 0x00, 0x18, 0x02, 0x04, 0x03, 0x84, 0x02, 0x44, 0x02,
	0x38, 0x02, 0x00, 0x00, 0x08, 0x01, 0x04, 0x02, 0x24, 0x02, 0x24, 0x02, 0xd8, 0x01, 0x00, 0x00,
	0xc0, 0x00, 0xa0, 0x00, 0x90, 0x00, 0x88, 0x00, 0xfc, 0x03, 0x00, 0x00, 0x3c, 0x01, 0x24, 0x02,
	0x24, 0x02, 0x24, 0x02, 0xc4, 0x01, 0x00, 0x00, 0xf8, 0x01, 0x24, 0x02, 0x24, 0x02, 0x24, 0x02,
	0xc0, 0x01, 0x00, 0x00, 0x04, 0x00, 0x04, 0x00, 0x84, 0x03, 0x64, 0x00, 0x1c, 0x00, 0x00, 0x00,
	0xd8, 0x01, 0x24, 0x02, 0x24, 0x02, 0x24, 0x02, 0xd8, 0x01, 0x00, 0x00, 0x38, 0x00, 0x44, 0x02,
	0x44, 0x02, 0x44, 0x02, 0xf8, 0x01, 0x00, 0x00, 0x00, 0x00, 0x00, 0x00, 0x30, 0x03, 0x00, 0x00,
	0x00, 0x00, 0x00, 0x00, 0x00, 0x00, 0x00, 0x04, 0x30, 0x03, 0x00, 0x00, 0x00, 0x00, 0x00, 0x00,
	0x00, 0x00, 0x40, 0x00, 0xa0, 0x00, 0x10, 0x01, 0x08, 0x02, 0x00, 0x00, 0x90, 0x00, 0x90, 0x00,
	0x90, 0x00, 0x90, 0x00, 0x90, 0x00, 0x00, 0x00, 0x00, 0x00, 0x08, 0x02, 0x10, 0x01, 0xa0, 0x00,
	0x40, 0x00, 0x00, 0x00, 0x18, 0x00, 0x04, 0x00, 0x44, 0x03, 0x24, 0x00, 0x18, 0x00, 0x00, 0x00,
	0xf8, 0x01, 0x04, 0x02, 0x64, 0x02, 0x94, 0x02, 0xf8, 0x02, 0x00, 0x00, 0xf8, 0x03, 0x44, 0x00,
	0x44, 0x00, 0x44, 0x00, 0xf8, 0x03, 0x00, 0x00, 0xfc, 0x03, 0x24, 0x02, 0x24, 0x02, 0x24, 0x02,
	0xd8, 0x01, 0x00, 0x00, 0xf8, 0x01, 0x04, 0x02, 0x04, 0x02, 0x04, 0x02, 0x08, 0x01, 0x00, 0x00,
	0xfc, 0x03, 0x04, 0x02, 0x04, 0x02, 0x08, 0x01, 0xf0, 0x00, 0x00, 0x00, 0xfc, 0x03, 0x24, 0x02,
	0x24, 0x02, 0x24, 0x02, 0x04, 0x02, 0x00, 0x00, 0xfc, 0x03, 0x24, 0x00, 0x24, 0x00, 0x24, 0x00,
	0x04, 0x00, 0x00, 0x00, 0xf8, 0x01, 0x04, 0x02, 0x44, 0x02, 0x44, 0x02, 0xc8, 0x01, 0x00, 0x00,
	0xfc, 0x03, 0x20, 0x00, 0x20, 0x00, 0x20, 0x00, 0xfc, 0x03, 0x00, 0x00, 0x00, 0x00, 0x04, 0x02,
	0xfc, 0x03, 0x04, 0x02, 0x00, 0x00, 0x00, 0x00, 0x80, 0x01, 0x00, 0x02, 0x04, 0x02, 0xfc, 0x01,
	0x04, 0x00, 0x00, 0x00, 0xfc, 0x03, 0x60, 0x00, 0x90, 0x00, 0x08, 0x01, 0x04, 0x02, 0x00, 0x00,
	0xfc, 0x03, 0x00, 0x02, 0x00, 0x02, 0x00, 0x02, 0x00, 0x02, 0x00, 0x00, 0xfc, 0x03, 0x08, 0x00,
	0x30, 0x00, 0x08, 0x00, 0xfc, 0x03, 0x00, 0x00, 0xfc, 0x03, 0x10, 0x00, 0x20, 0x00, 0x40, 0x00,
	0xfc, 0x03, 0x00, 0x00, 0xf8, 0x01, 0x04, 0x02, 0x04, 0x02, 0x04, 0x02, 0xf8, 0x01, 0x00, 0x00,
	0xfc, 0x03, 0x44, 0x00, 0x44, 0x00, 0x44, 0x00, 0x38, 0x00, 0x00, 0x00, 0xf8, 0x01, 0x04, 0x02,
	0x04, 0x03, 0x04, 0x02, 0xf8, 0x05, 0x00, 0x00, 0xfc, 0x03, 0x44, 0x00, 0xc4, 0x00, 0x44, 0x01,
	0x38, 0x02, 0x00, 0x00, 0x18, 0x01, 0x24, 0x02, 0x24, 0x02, 0x24, 0x02, 0xc8, 0x01, 0x00, 0x00,
	0x04, 0x00, 0x04, 0x00, 0xfc, 0x03, 0x04, 0x00, 0x04, 0x00, 0x00, 0x00, 0xfc, 0x01, 0x00, 0x02,
	0x00, 0x02, 0x00, 0x02, 0xfc, 0x01, 0x00, 0x00, 0x1c, 0x00, 0xe0, 0x00, 0x00, 0x03, 0xe0, 0x00,
	0x1c, 0x00, 0x00, 0x00, 0xfc, 0x03, 0x00, 0x01, 0xc0, 0x00, 0x00, 0x01, 0xfc, 0x03, 0x00, 0x00,
	0x0c, 0x03, 0x90, 0x00, 0x60, 0x00, 0x90, 0x00, 0x0c, 0x03, 0x00, 0x00, 0x0c, 0x00, 0x30, 0x00,
	0xc0, 0x03, 0x30, 0x00, 0x0c, 0x00, 0x00, 0x00, 0x84, 0x03, 0x44, 0x02, 0x24, 0x02, 0x14, 0x02,
	0x0c, 0x02, 0x00, 0x00, 0x00, 0x00, 0xfc, 0x03, 0x04, 0x02, 0x04, 0x02, 0x00, 0x00, 0x00, 0x00,
	0x00, 0x00, 0x0c, 0x00, 0x30, 0x00, 0xc0, 0x00, 0x00, 0x03, 0x00, 0x00, 0x00, 0x00, 0x04, 0x02,
	0x04, 0x02, 0xfc, 0x03, 0x00, 0x00, 0x00, 0x00, 0x08, 0x00, 0x04, 0x00, 0x02, 0x00, 0x04, 0x00,
	0x08, 0x00, 0x00, 0x00, 0x00, 0x04, 0x00, 0x04, 0x00, 0x04, 0x00, 0x04, 0x00, 0x04, 0x00, 0x00,
	0x00, 0x00, 0x01, 0x00, 0x02, 0x00, 0x00, 0x00, 0x00, 0x00, 0x00, 0x00, 0x80, 0x01, 0x50, 0x02,
	0x50, 0x02, 0x50, 0x02, 0xe0, 0x03, 0x00, 0x00, 0xfc, 0x03, 0x10, 0x02, 0x10, 0x02, 0x10, 0x02,
	0xe0, 0x01, 0x00, 0x00, 0xe0, 0x01, 0x10, 0x02, 0x10, 0x02, 0x10, 0x02, 0x20, 0x01, 0x00, 0x00,
	0xe0, 0x01, 0x10, 0x02, 0x10, 0x02, 0x10, 0x02, 0xfc, 0x03, 0x00, 0x00, 0xe0, 0x01, 0x50, 0x02,
	0x50, 0x02, 0x50, 0x02, 0x60, 0x02, 0x00, 0x00, 0x00, 0x00, 0x10, 0x00, 0xf8, 0x03, 0x14, 0x00,
	0x04, 0x00, 0x00, 0x00, 0xe0, 0x01, 0x10, 0x0a, 0x10, 0x0a, 0x10, 0x0a, 0xf0, 0x07, 0x00, 0x00,
	0xfc, 0x03, 0x10, 0x00, 0x10, 0x00, 0x10, 0x00, 0xe0, 0x03, 0x00, 0x00, 0x00, 0x00, 0x10, 0x02,
	0xf6, 0x03, 0x00, 0x02, 0x00, 0x00, 0x00, 0x00, 0x00, 0x00, 0x00, 0x04, 0x00, 0x08, 0x10, 0x08,
	0xf6, 0x07, 0x00, 0x00, 0x00, 0x00, 0xfc, 0x03, 0xc0, 0x00, 0x20, 0x01, 0x10, 0x02, 0x00, 0x00,
	0x00, 0x00, 0x04, 0x02, 0xfc, 0x03, 0x00, 0x02, 0x00, 0x00, 0x00, 0x00, 0xf0, 0x03, 0x10, 0x00,
	0xf0, 0x03, 0x10, 0x00, 0xe0, 0x03, 0x00, 0x00, 0xf0, 0x03, 0x10, 0x00, 0x10, 0x00, 0x10, 0x00,
	0xe0, 0x03, 0x00, 0x00, 0xe0, 0x01, 0x10, 0x02, 0x10, 0x02, 0x10, 0x02, 0xe0, 0x01, 0x00, 0x00,
	0xf0, 0x0f, 0x10, 0x02, 0x10, 0x02, 0x10, 0x02, 0xe0, 0x01, 0x00, 0x00, 0xe0, 0x01, 0x10, 0x02,
	0x10, 0x02, 0x10, 0x02, 0xf0, 0x0f, 0x00, 0x00, 0xf0, 0x03, 0x20, 0x00, 0x10, 0x00, 0x10, 0x00,
	0x10, 0x00, 0x00, 0x00, 0x20, 0x02, 0x50, 0x02, 0x50, 0x02, 0x50, 0x02, 0x90, 0x01, 0x00, 0x00,
	0x00, 0x00, 0x10, 0x00, 0xfc, 0x01, 0x10, 0x02, 0x00, 0x02, 0x00, 0x00, 0xf0, 0x01, 0x00, 0x02,
	0x00, 0x02, 0x00, 0x02, 0xf0, 0x03, 0x00, 0x00, 0x30, 0x00, 0xc0, 0x00, 0x00, 0x03, 0xc0, 0x00,
	0x30, 0x00, 0x00, 0x00, 0xf0, 0x01, 0x00, 0x02, 0xc0, 0x03, 0x00, 0x02, 0xf0, 0x01, 0x00, 0x00,
	0x10, 0x02, 0x20, 0x01, 0xc0, 0x00, 0x20, 0x01, 0x10, 0x02, 0x00, 0x00, 0xf0, 0x01, 0x00, 0x0a,
	0x00, 0x0a, 0x00, 0x0a, 0xf0, 0x07, 0x00, 0x00, 0x10, 0x03, 0x90, 0x02, 0x50, 0x02, 0x30, 0x02,
	0x10, 0x02, 0x00, 0x00, 0x00, 0x00, 0x20, 0x00, 0xd8, 0x01, 0x04, 0x02, 0x04, 0x02, 0x00, 0x00,
	0x00, 0x00, 0x00, 0x00, 0xfc, 0x03, 0x00, 0x00, 0x00, 0x00, 0x00, 0x00, 0x00, 0x00, 0x04, 0x02,
	0x04, 0x02, 0xd8, 0x01, 0x20, 0x00, 0x00, 0x00, 0x0c, 0x00, 0x02, 0x00, 0x04, 0x00, 0x08, 0x00,
	0x06, 0x00, 0x00, 0x00, 0xf8, 0x03, 0x44, 0x00, 0x44, 0x00, 0x44, 0x00, 0xf8, 0x03, 0x00, 0x00,
	0xfc, 0x03, 0x24, 0x02, 0x24, 0x02, 0x24, 0x02, 0xc0, 0x01, 0x00, 0x00, 0xfc, 0x03, 0x24, 0x02,
	0x24, 0x02, 0x24, 0x02, 0xd8, 0x01, 0x00, 0x00, 0xfc, 0x03, 0x04, 0x00, 0x04, 0x00, 0x04, 0x00,
	0x04, 0x00, 0x00, 0x00, 0x00, 0x06, 0xf8, 0x03, 0x04, 0x02, 0x04, 0x02, 0xfc, 0x03, 0x00, 0x06,
	0xfc, 0x03, 0x24, 0x02, 0x24, 0x02, 0x24, 0x02, 0x04, 0x02, 0x00, 0x00, 0x9c, 0x03, 0x60, 0x00,
	0xfc, 0x03, 0x60, 0x00, 0x9c, 0x03, 0x00, 0x00, 0x08, 0x01, 0x04, 0x02, 0x24, 0x02, 0x24, 0x02,
	0xd8, 0x01, 0x00, 0x00, 0xfc, 0x03, 0x40, 0x00, 0x20, 0x00, 0x10, 0x00, 0xfc, 0x03, 0x00, 0x00,
	0xfc, 0x03, 0x41, 0x00, 0x22, 0x00, 0x11, 0x00, 0xfc, 0x03, 0x00, 0x00, 0xfc, 0x03, 0x60, 0x00,
	0x90, 0x00, 0x08, 0x01, 0x04, 0x02, 0x00, 0x00, 0x00, 0x02, 0xf8, 0x01, 0x04, 0x00, 0x04, 0x00,
	0xfc, 0x03, 0x00, 0x00, 0xfc, 0x03, 0x08, 0x00, 0x30, 0x00, 0x08, 0x00, 0xfc, 0x03, 0x00, 0x00,
	0xfc, 0x03, 0x20, 0x00, 0x20, 0x00, 0x20, 0x00, 0xfc, 0x03, 0x00, 0x00, 0xf8, 0x01, 0x04, 0x02,
	0x04, 0x02, 0x04, 0x02, 0xf8, 0x01, 0x00, 0x00, 0xfc, 0x03, 0x04, 0x00, 0x04, 0x00, 0x04, 0x00,
	0xfc, 0x03, 0x00, 0x00, 0xfc, 0x03, 0x44, 0x00, 0x44, 0x00, 0x44, 0x00, 0x38, 0x00, 0x00, 0x00,
	0xf8, 0x01, 0x04, 0x02, 0x04, 0x02, 0x04, 0x02, 0x08, 0x01, 0x00, 0x00, 0x04, 0x00, 0x04, 0x00,
	0xfc, 0x03, 0x04, 0x00, 0x04, 0x00, 0x00, 0x00, 0x3c, 0x00, 0x40, 0x02, 0x40, 0x02, 0x40, 0x02,
	0xfc, 0x01, 0x00, 0x00, 0xf8, 0x01, 0x04, 0x02, 0xfe, 0x07, 0x04, 0x02, 0xf8, 0x01, 0x00, 0x00,
	0x0c, 0x03, 0x90, 0x00, 0x60, 0x00, 0x90, 0x00, 0x0c, 0x03, 0x00, 0x00, 0xfc, 0x01, 0x00, 0x02,
	0x00, 0x02, 0x00, 0x02, 0xfc, 0x03, 0x00, 0x0e, 0x3c, 0x00, 0x40, 0x00, 0x40, 0x00, 0x40, 0x00,
	0xfc, 0x03, 0x00, 0x00, 0xfc, 0x01, 0x00, 0x02, 0xfc, 0x03, 0x00, 0x02, 0xfc, 0x03, 0x00, 0x00,
	0xfc, 0x01, 0x00, 0x02, 0xfc, 0x03, 0x00, 0x02, 0xfc, 0x03, 0x00, 0x0e, 0x04, 0x00, 0xfc, 0x03,
	0x10, 0x02, 0x10, 0x02, 0xe0, 0x01, 0x00, 0x00, 0xfc, 0x03, 0x10, 0x02, 0xe0, 0x01, 0x00, 0x00,
	0xfc, 0x03, 0x00, 0x00, 0x00, 0x00, 0xfc, 0x03, 0x10, 0x02, 0x10, 0x02, 0xe0, 0x01, 0x00, 0x00,
	0x08, 0x01, 0x04, 0x02, 0x24, 0x02, 0x24, 0x02, 0xf8, 0x01, 0x00, 0x00, 0xfc, 0x03, 0x40, 0x00,
	0xf8, 0x01, 0x04, 0x02, 0xf8, 0x01, 0x00, 0x00, 0x38, 0x02, 0x44, 0x01, 0xc4, 0x00, 0x44, 0x00,
	0xfc, 0x03, 0x00, 0x00, 0x80, 0x01, 0x50, 0x02, 0x50, 0x02, 0x50, 0x02, 0xe0, 0x03, 0x00, 0x00,
	0xf8, 0x03, 0x14, 0x02, 0x14, 0x02, 0x14, 0x02, 0xe0, 0x01, 0x00, 0x00, 0xfc, 0x03, 0x24, 0x02,
	0x24, 0x02, 0x38, 0x02, 0xc0, 0x01, 0x00, 0x00, 0xf0, 0x03, 0x10, 0x00, 0x10, 0x00, 0x10, 0x00,
	0x10, 0x00, 0x00, 0x00, 0x00, 0x06, 0xe0, 0x03, 0x10, 0x02, 0x10, 0x02, 0xf0, 0x03, 0x00, 0x06,
	0xe0, 0x01, 0x50, 0x02, 0x50, 0x02, 0x50, 0x02, 0x60, 0x02, 0x00, 0x00, 0xb0, 0x03, 0x40, 0x00,
	0xf0, 0x03, 0x40, 0x00, 0xb0, 0x03, 0x00, 0x00, 0x20, 0x01, 0x10, 0x02, 0x50, 0x02, 0x50, 0x02,
	0xa0, 0x01, 0x00, 0x00, 0xf0, 0x01, 0x00, 0x02, 0x00, 0x02, 0x00, 0x02, 0xf0, 0x03, 0x00, 0x00,
	0xf0, 0x01, 0x04, 0x02, 0x08, 0x02, 0x04, 0x02, 0xf0, 0x03, 0x00, 0x00, 0x00, 0x00, 0xf0, 0x03,
	0xc0, 0x00, 0x20, 0x01, 0x10, 0x02, 0x00, 0x00, 0x00, 0x02, 0xe0, 0x01, 0x10, 0x00, 0x10, 0x00,
	0xf0, 0x03, 0x00, 0x00, 0xf0, 0x03, 0x20, 0x00, 0x40, 0x00, 0x20, 0x00, 0xf0, 0x03, 0x00, 0x00,
	0xf0, 0x03, 0x40, 0x00, 0x40, 0x00, 0x40, 0x00, 0xf0, 0x03, 0x00, 0x00, 0xe0, 0x01, 0x10, 0x02,
	0x10, 0x02, 0x10, 0x02, 0xe0, 0x01, 0x00, 0x00, 0xf0, 0x03, 0x10, 0x00, 0x10, 0x00, 0x10, 0x00,
	0xf0, 0x03, 0x00, 0x00, 0xf0, 0x0f, 0x10, 0x02, 0x10, 0x02, 0x10, 0x02, 0xe0, 0x01, 0x00, 0x00,
	0xe0, 0x01, 0x10, 0x02, 0x10, 0x02, 0x10, 0x02, 0x20, 0x01, 0x00, 0x00, 0x10, 0x00, 0x10, 0x00,
	0xf0, 0x03, 0x10, 0x00, 0x10, 0x00, 0x00, 0x00, 0xf0, 0x01, 0x00, 0x0a, 0x00, 0x0a, 0x00, 0x0a,
	0xf0, 0x07, 0x00, 0x00, 0xe0, 0x01, 0x10, 0x02, 0xf8, 0x07, 0x10, 0x02, 0xe0, 0x01, 0x00, 0x00,
	0x10, 0x02, 0x20, 0x01, 0xc0, 0x00, 0x20, 0x01, 0x10, 0x02, 0x00, 0x00, 0xf0, 0x01, 0x00, 0x02,
	0x00, 0x02, 0x00, 0x02, 0xf0, 0x03, 0x00, 0x0e, 0x70, 0x00, 0x80, 0x00, 0x80, 0x00, 0x80, 0x00,
	0xf0, 0x03, 0x00, 0x00, 0xf0, 0x01, 0x00, 0x02, 0xf0, 0x03, 0x00, 0x02, 0xf0, 0x03, 0x00, 0x00,
	0xf0, 0x01, 0x00, 0x02, 0xf0, 0x03, 0x00, 0x02, 0xf0, 0x03, 0x00, 0x0e, 0x10, 0x00, 0xf0, 0x03,
	0x40, 0x02, 0x40, 0x02, 0x80, 0x01, 0x00, 0x00, 0xf0, 0x03, 0x40, 0x02, 0x80, 0x01, 0x00, 0x00,
	0xf0, 0x03, 0x00, 0x00, 0x00, 0x00, 0xf0, 0x03, 0x40, 0x02, 0x40, 0x02, 0x80, 0x01, 0x00, 0x00,
	0x20, 0x01, 0x10, 0x02, 0x50, 0x02, 0x50, 0x02, 0xe0, 0x01, 0x00, 0x00, 0xf0, 0x03, 0x80, 0x00,
	0xe0, 0x01, 0x10, 0x02, 0xe0, 0x01, 0x00, 0x00, 0x60, 0x00, 0x90, 0x02, 0x90, 0x01, 0x90, 0x00,
	0xf0, 0x03, 0x00, 0x00, 0xf8, 0x01, 0x24, 0x02, 0x24, 0x02, 0x24, 0x02, 0x08, 0x01, 0x00, 0x00,
	0x00, 0x00, 0x04, 0x02, 0xfc, 0x03, 0x04, 0x02, 0x00, 0x00, 0x00, 0x00, 0x00, 0x00, 0x07, 0x02,
	0xfc, 0x03, 0x07, 0x02, 0x00, 0x00, 0x00, 0x00, 0xfc, 0x03, 0x04, 0x00, 0x04, 0x00, 0x04, 0x00,
	0x07, 0x00, 0x00, 0x00, 0xe0, 0x01, 0x50, 0x02, 0x50, 0x02, 0x10, 0x02, 0x20, 0x01, 0x00, 0x00,
	0x00, 0x00, 0x10, 0x02, 0xf6, 0x03, 0x00, 0x02, 0x00, 0x00, 0x00, 0x00, 0x00, 0x00, 0x1c, 0x02,
	0xf0, 0x03, 0x0c, 0x02, 0x00, 0x00, 0x00, 0x00, 0xf0, 0x03, 0x10, 0x00, 0x10, 0x00, 0x10, 0x00,
	0x1c, 0x00, 0x00, 0x00, 0x00, 0x00, 0x04, 0x00, 0x0a, 0x00, 0x04, 0x00, 0x00, 0x00, 0x00, 0x00,
	0x00, 0x03, 0x00, 0x00, 0x00, 0x03, 0x00, 0x00, 0x00, 0x03, 0x00, 0x00, 0x40, 0x00, 0x40, 0x00,
	0x40, 0x00, 0x40, 0x00, 0x40, 0x00, 0x00, 0x00, 0x40, 0x00, 0x40, 0x00, 0x40, 0x00, 0x40, 0x00,
	0x40, 0x00, 0x00, 0x00, 0x40, 0x00, 0xa0, 0x00, 0x50, 0x01, 0xa8, 0x02, 0x10, 0x01, 0x08, 0x02,
	0x08, 0x02, 0x10, 0x01, 0xa8, 0x02, 0x50, 0x01, 0xa0, 0x00, 0x40, 0x00, 0x00, 0x00, 0x08, 0x00,
	0x06, 0x00, 0x00, 0x00, 0x00, 0x00, 0x00, 0x00, 0xfc, 0x03, 0x70, 0x00, 0xe0, 0x00, 0xfc, 0x03,
	0x00, 0x00, 0x8c, 0x02,
};
static const struct font_glyph font_glyphs[] = {
	{0x0020, 6, 6, 0},
	{0x0021, 6, 6, 12},
	{0x0022, 6, 6, 24},
	{0x0023, 6, 6, 36},
	{0x0024, 6, 6, 48},
	{0x0025, 6, 6, 60},
	{0x0026, 6, 6, 72},
	{0x0027, 6, 6, 84},
	{0x0028, 6, 6, 96},
	{0x0029, 6, 6, 108},
	{0x002a, 6, 6, 120},
	{0x002b, 6, 6, 132},
	{0x002c, 6, 6, 144},
	{0x002d, 6, 6, 156},
	{0x002e, 6, 6, 168},
	{0x002f, 6, 6, 180},
	{0x0030, 6, 6, 192},
	{0x0031, 6, 6, 204},
	{0x0032, 6, 6, 216},
	{0x0033, 6, 6, 228},
	{0x0034, 6, 6, 240},
	{0x0035, 6, 6, 252},
	{0x0036, 6, 6, 264},
	{0x0037, 6, 6, 276},
	{0x0038, 6, 6, 288},
	{0x0039, 6, 6, 300},
	{0x003a, 6, 6, 312},
	{0x003b, 6, 6, 324},
	{0x003c, 6, 6, 336},
	{0x003d, 6, 6, 348},
	{0x003e, 6, 6, 360},
	{0x003f, 6, 6, 372},
	{0x0040, 6, 6, 384},
	{0x0041, 6, 6, 396},
	{0x0042, 6, 6, 408},
	{0x0043, 6, 6, 420},
	{0x0044, 6, 6, 432},
	{0x0045, 6, 6, 444},
	{0x0046, 6, 6, 456},
	{0x0047, 6, 6, 468},
	{0x0048, 6, 6, 480},
	{0x0049, 6, 6, 492},
	{0x004a, 6, 6, 504},
	{0x004b, 6, 6, 516},
	{0x004c, 6, 6, 528},
	{0x004d, 6, 6, 540},
	{0x004e, 6, 6, 552},
	{0x004f, 6, 6, 564},
	{0x0050, 6, 6, 576},
	{0x0051, 6, 6, 588},
	{0x0052, 6, 6, 600},
	{0x0053, 6, 6, 612},
	{0x0054, 6, 6, 624},
	{0x0055, 6, 6, 636},
	{0x0056, 6, 6, 648},
	{0x0057, 6, 6, 660},
	{0x0058, 6, 6, 672},
	{0x0059, 6, 6, 684},
	{0x005a, 6, 6, 696},
	{0x005b, 6, 6, 708},
	{0x005c, 6, 6, 720},
	{0x005d, 6, 6, 732},
	{0x005e, 6, 6, 744},
	{0x005f, 6, 6, 756},
	{0x0060, 6, 6, 768},
	{0x0061, 6, 6, 780},
	{0x0062, 6, 6, 792},
	{0x0063, 6, 6, 804},
	{0x0064, 6, 6, 816},
	{0x0065, 6, 6, 828},
	{0x0066, 6, 6, 840},
	{0x0067, 6, 6, 852},
	{0x0068, 6, 6, 864},
	{0x0069, 6, 6, 876},
	{0x006a, 6, 6, 888},
	{0x006b, 6, 6, 900},
	{0x006c, 6, 6, 912},
	{0x006d, 6, 6, 924},
	{0x006e, 6, 6, 936},
	{0x006f, 6, 6, 948},
	{0x0070, 6, 6, 960},
	{0x0071, 6, 6, 972},
	{0x0072, 6, 6, 984},
	{0x0073, 6, 6, 996},
	{0x0074, 6, 6, 1008},
	{0x0075, 6, 6, 1020},
	{0x0076, 6, 6, 1032},
	{0x0077, 6, 6, 1044},
	{0x0078, 6, 6, 1056},
	{0x0079, 6, 6, 1068},
	{0x007a, 6, 6, 1080},
	{0x007b, 6, 6, 1092},
	{0x007c, 6, 6, 1104},
	{0x007d, 6, 6, 1116},
	{0x007e, 6, 6, 1128},
	{0x00ab, 6, 6, 2052},
	{0x00b0, 6, 6, 2004},
	{0x00bb, 6, 6, 2064},
	{0x0404, 6, 6, 1908},
	{0x0406, 6, 6, 1920},
	{0x0407, 6, 6, 1932},
	{0x0410, 6, 6, 1140},
	{0x0411, 6, 6, 1152},
	{0x0412, 6, 6, 1164},
	{0x0413, 6, 6, 1176},
	{0x0414, 6, 6, 1188},
	{0x0415, 6, 6, 1200},
	{0x0416, 6, 6, 1212},
	{0x0417, 6, 6, 1224},
	{0x0418, 6, 6, 1236},
	{0x0419, 6, 6, 1248},
	{0x041a, 6, 6, 1260},
	{0x041b, 6, 6, 1272},
	{0x041c, 6, 6, 1284},
	{0x041d, 6, 6, 1296},
	{0x041e, 6, 6, 1308},
	{0x041f, 6, 6, 1320},
	{0x0420, 6, 6, 1332},
	{0x0421, 6, 6, 1344},
	{0x0422, 6, 6, 1356},
	{0x0423, 6, 6, 1368},
	{0x0424, 6, 6, 1380},
	{0x0425, 6, 6, 1392},
	{0x0426, 6, 6, 1404},
	{0x0427, 6, 6, 1416},
	{0x0428, 6, 6, 1428},
	{0x0429, 6, 6, 1440},
	{0x042a, 6, 6, 1452},
	{0x042b, 6, 6, 1464},
	{0x042c, 6, 6, 1476},
	{0x042d, 6, 6, 1488},
	{0x042e, 6, 6, 1500},
	{0x042f, 6, 6, 1512},
	{0x0430, 6, 6, 1524},
	{0x0431, 6, 6, 1536},
	{0x0432, 6, 6, 1548},
	{0x0433, 6, 6, 1560},
	{0x0434, 6, 6, 1572},
	{0x0435, 6, 6, 1584},
	{0x0436, 6, 6, 1596},
	{0x0437, 6, 6, 1608},
	{0x0438, 6, 6, 1620},
	{0x0439, 6, 6, 1632},
	{0x043a, 6, 6, 1644},
	{0x043b, 6, 6, 1656},
	{0x043c, 6, 6, 1668},
	{0x043d, 6, 6, 1680},
	{0x043e, 6, 6, 1692},
	{0x043f, 6, 6, 1704},
	{0x0440, 6, 6, 1716},
	{0x0441, 6, 6, 1728},
	{0x0442, 6, 6, 1740},
	{0x0443, 6, 6, 1752},
	{0x0444, 6, 6, 1764},
	{0x0445, 6, 6, 1776},
	{0x0446, 6, 6, 1788},
	{0x0447, 6, 6, 1800},
	{0x0448, 6, 6, 1812},
	{0x0449, 6, 6, 1824},
	{0x044a, 6, 6, 1836},
	{0x044b, 6, 6, 1848},
	{0x044c, 6, 6, 1860},
	{0x044d, 6, 6, 1872},
	{0x044e, 6, 6, 1884},
	{0x044f, 6, 6, 1896},
	{0x0454, 6, 6, 1956},
	{0x0456, 6, 6, 1968},
	{0x0457, 6, 6, 1980},
	{0x0490, 6, 6, 1944},
	{0x0491, 6, 6, 1992},
	{0x2013, 6, 6, 2040},
	{0x2014, 6, 6, 2028},
	{0x2019, 6, 6, 2076},
	{0x2026, 6, 6, 2016},
	{0x2116, 6, 6, 2088},
};
const struct font font_main = { 12, 10, font_glyphs, 175, font_data };
```

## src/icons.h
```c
#pragma once
#include <stdint.h>
struct icon {
	const char *name;
	const uint32_t *rows; /* 24 rows, bit x = column x */
};
extern const struct icon icons[];
extern const int icons_count;
```

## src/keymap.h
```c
#pragma once
/* Button N (1..14) = pair of keypad lines (0-based index into kp-gpios).
 * Lines: 0 = 106 (IC GND), 1 = 104, 2 = 009, 3 = 010, 4 = 111, 5 = 011.
 * Learned 2026-11-22 on the second board (buttons on line 4/111 derived from the PCB layout).
 * Pair 3-5 (0-based) is unused on this PCB. Front-panel labels: see README. */
static const signed char keymap[14][2] = {
	{3, 4}, /*  1: 010-111  ⏻ power */
	{2, 3}, /*  2: 009-010  ⟳ сцени */
	{2, 5}, /*  3: 009-011  (blank) домофон */
	{2, 4}, /*  4: 009-111  ☼ up */
	{1, 3}, /*  5: 104-010  K- → room ◀ */
	{1, 4}, /*  6: 104-111  ☾ night */
	{1, 5}, /*  7: 104-011  K+ → room ▶ */
	{4, 5}, /*  8: 111-011  ☼ down */
	{0, 3}, /*  9: 106-010  20% */
	{0, 4}, /* 10: 106-111  50% */
	{0, 5}, /* 11: 106-011  100% */
	{0, 1}, /* 12: 106-104  3000K → hot 1 */
	{0, 2}, /* 13: 106-009  6500K → hot 2 */
	{1, 2}, /* 14: 104-009  4000K → hot 3 */
};
```
